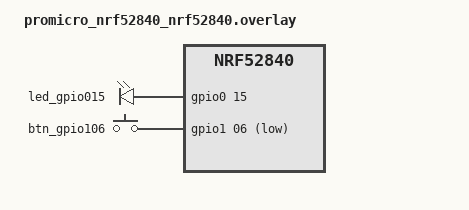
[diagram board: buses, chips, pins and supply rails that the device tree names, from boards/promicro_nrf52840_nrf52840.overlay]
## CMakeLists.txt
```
cmake_minimum_required(VERSION 3.20.0)

find_package(Zephyr)
project(keebz)

target_sources(app PRIVATE src/keebz_usb_hid.c src/keebz_usb_dev.c)
```

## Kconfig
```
# SPDX-License-Identifier: Apache-2.0

mainmenu "Keebz"

menu "Application"

config KEEBZ_USB_HID_LOG_LEVEL
	int "Keebz USB HID thread log level"
	depends on LOG
	default 0

config KEEBZ_USB_DEV_LOG_LEVEL
	int "Keebz USB device thread log level"
	depends on LOG
	default 0

config KEEBZ_USB_DEV_VENDOR_ID
	hex "Keebz USB device vendor id"
	default 0x0000

config KEEBZ_USB_DEV_PRODUCT_ID
	hex "Keebz USB device product id"
	default 0x0000

config KEEBZ_USB_DEV_MANUFACTURER
	string "Keebz USB device manufacturer string"
	default "Unknown"

config KEEBZ_USB_DEV_PRODUCT
	string "Keebz USB device product string"
	default "Unknown"

config KEEBZ_USB_DEV_SELF_POWERED
	bool "Keebz USB device self-powered attribute"
	default n

config KEEBZ_USB_DEV_REMOTE_WAKEUP
	bool "Keebz USB device remote wakeup attribute"
	default n

config KEEBZ_USB_DEV_MAX_POWER
	int "Keebz USB device max power value (in 2mA units)"
	default 125
	range 0 250

config KEEBZ_USB_DEV_20_EXT_DESC
	bool "Keebz USB device to use USB 2.0 extension descriptor"
	default true

endmenu

source "Kconfig.zephyr"
```

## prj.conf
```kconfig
CONFIG_ASSERT=y
CONFIG_GPIO=y
CONFIG_POLL=y
CONFIG_SCHED_DUMB=y

CONFIG_SERIAL=y
CONFIG_CONSOLE=y
CONFIG_UART_CONSOLE=y
CONFIG_INPUT=y
CONFIG_INPUT_GPIO_KEYS=y

CONFIG_LOG=y
CONFIG_LOG_MODE_DEFERRED=y
CONFIG_LOG_DEFAULT_LEVEL=0
CONFIG_LOG_BACKEND_UART=y

CONFIG_USB_DEVICE_STACK=n
CONFIG_USB_CDC_ACM=n
CONFIG_USB_DEVICE_STACK_NEXT=y
CONFIG_USBD_HID_SUPPORT=y

# CONFIG_USBD_LOG_LEVEL_DBG=y
# CONFIG_UDC_DRIVER_LOG_LEVEL_DBG=y
# CONFIG_NRF_USBD_COMMON_LOG_LEVEL_DBG=y
CONFIG_KEEBZ_USB_HID_LOG_LEVEL=4
CONFIG_KEEBZ_USB_DEV_LOG_LEVEL=4
CONFIG_KEEBZ_USB_DEV_VENDOR_ID=0x2fe3
CONFIG_KEEBZ_USB_DEV_PRODUCT_ID=0x0007
CONFIG_KEEBZ_USB_DEV_MANUFACTURER="Boardsource"
CONFIG_KEEBZ_USB_DEV_PRODUCT="Microdox Bud v2"
```

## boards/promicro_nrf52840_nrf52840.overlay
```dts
/ {
	chosen {
		zephyr,console = &uart0;
	};
	aliases {
		led-alive = &led_gpio015;
		btn-key = &btn_gpio106;
 		hid-kbd = &hid_kbd0;
	};
	leds {
		compatible = "gpio-leds";
		led_gpio015: led_gpio015 {
			gpios = <&gpio0 15 GPIO_ACTIVE_HIGH>;
			status = "okay";
		};
	};
	buttons {
		compatible = "gpio-keys";
		btn_gpio106: btn_gpio106 {
			zephyr,code = <INPUT_KEY_0>;
			gpios = <&gpio1 06 (GPIO_PULL_UP | GPIO_ACTIVE_LOW)>;
			status = "okay";
		};
	};
	hid_kbd0: hid_kbd0 {
		compatible = "zephyr,hid-device";
		interface-name = "HID0";
		protocol-code = "keyboard";
		in-report-size = <64>;
		in-polling-period-us = <125>;
		out-report-size = <64>;
		out-polling-period-us = <125>;
		status = "okay";
	};
};
```

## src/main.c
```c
#include <stdio.h>
#include <zephyr/kernel.h>
#include <zephyr/drivers/gpio.h>

#define SLEEP_TIME_MS 200

#define LED0_NODE DT_ALIAS(led_alive)

static const struct gpio_dt_spec led = GPIO_DT_SPEC_GET(LED0_NODE, gpios);

int main(void)
{
	int ret;
	bool led_state = true;

	if (!gpio_is_ready_dt(&led)) {
		return 0;
	}

	ret = gpio_pin_configure_dt(&led, GPIO_OUTPUT_ACTIVE);
	if (ret < 0) {
		return 0;
	}

	while (1) {
		ret = gpio_pin_toggle_dt(&led);
		if (ret < 0) {
			return 0;
		}

		led_state = !led_state;
		printf("LED state: %s\n", led_state ? "ON" : "OFF");
		k_msleep(SLEEP_TIME_MS);
	}
	return 0;
}
```

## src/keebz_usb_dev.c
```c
#include <stdint.h>

#include <zephyr/device.h>
#include <zephyr/usb/usbd.h>
#include <zephyr/usb/bos.h>
#include <zephyr/logging/log.h>

#include "keebz_usb_dev.h"

LOG_MODULE_REGISTER(keebz_usb_dev, CONFIG_KEEBZ_USB_DEV_LOG_LEVEL);

USBD_DEVICE_DEFINE(keebz_usb_dev, DEVICE_DT_GET(DT_NODELABEL(zephyr_udc0)), CONFIG_KEEBZ_USB_DEV_VENDOR_ID,
		   CONFIG_KEEBZ_USB_DEV_PRODUCT_ID);

static const char *const keebz_usb_dev_blocklist[] = { "dfu_dfu", NULL };

USBD_DESC_LANG_DEFINE(keebz_usb_dev_lang);
USBD_DESC_MANUFACTURER_DEFINE(keebz_usb_dev_mfr, CONFIG_KEEBZ_USB_DEV_MANUFACTURER);
USBD_DESC_PRODUCT_DEFINE(keebz_usb_dev_product, CONFIG_KEEBZ_USB_DEV_PRODUCT);
USBD_DESC_SERIAL_NUMBER_DEFINE(keebz_usb_dev_serial);

USBD_DESC_CONFIG_DEFINE(keebz_usb_dev_fs_desc, "Full-speed configuration");
USBD_DESC_CONFIG_DEFINE(keebz_usb_dev_hs_desc, "High-speed configuration");

static const uint8_t attributes = (IS_ENABLED(CONFIG_KEEBZ_USB_DEV_SELF_POWERED) ? USB_SCD_SELF_POWERED : 0) |
				  (IS_ENABLED(CONFIG_KEEBZ_USB_DEV_REMOTE_WAKEUP) ? USB_SCD_REMOTE_WAKEUP : 0);

USBD_CONFIGURATION_DEFINE(keebz_usb_dev_fs_cfg, attributes, CONFIG_KEEBZ_USB_DEV_MAX_POWER, &keebz_usb_dev_fs_desc);
USBD_CONFIGURATION_DEFINE(keebz_usb_dev_hs_cfg, attributes, CONFIG_KEEBZ_USB_DEV_MAX_POWER, &keebz_usb_dev_hs_desc);

static const struct usb_bos_capability_lpm keebz_usb_dev_bos_cap_lpm = {
	.bLength = sizeof(struct usb_bos_capability_lpm),
	.bDescriptorType = USB_DESC_DEVICE_CAPABILITY,
	.bDevCapabilityType = USB_BOS_CAPABILITY_EXTENSION,
	.bmAttributes = 0UL,
};

USBD_DESC_BOS_DEFINE(keebz_usb_dev_ext_desc, sizeof(keebz_usb_dev_bos_cap_lpm), &keebz_usb_dev_bos_cap_lpm);

static void keebz_usb_dev_fix_code_triple(struct usbd_context *ctx, const enum usbd_speed speed)
{
	if (IS_ENABLED(CONFIG_USBD_CDC_ACM_CLASS) || IS_ENABLED(CONFIG_USBD_CDC_ECM_CLASS) ||
	    IS_ENABLED(CONFIG_USBD_CDC_NCM_CLASS) || IS_ENABLED(CONFIG_USBD_MIDI2_CLASS) ||
	    IS_ENABLED(CONFIG_USBD_AUDIO2_CLASS)) {
		usbd_device_set_code_triple(ctx, speed, USB_BCC_MISCELLANEOUS, 0x02, 0x01);
	} else {
		usbd_device_set_code_triple(ctx, speed, 0, 0, 0);
	}
}

struct usbd_context *keebz_usb_dev_init(usbd_msg_cb_t cb)
{
	int err;

	if (!keebz_usb_dev_setup(cb)) {
		LOG_ERR("Failed to setup device");
		return NULL;
	}

	err = usbd_init(&keebz_usb_dev);
	if (err) {
		LOG_ERR("Failed to initialize device support, err=%d", err);
		return NULL;
	}

	return &keebz_usb_dev;
}

struct usbd_context *keebz_usb_dev_setup(usbd_msg_cb_t cb)
{
	int err;

	err = usbd_add_descriptor(&keebz_usb_dev, &keebz_usb_dev_lang);
	if (err) {
		LOG_ERR("Failed to initialize language descriptor, err=%d", err);
		return NULL;
	}

	err = usbd_add_descriptor(&keebz_usb_dev, &keebz_usb_dev_mfr);
	if (err) {
		LOG_ERR("Failed to initialize manufacturer descriptor, err=%d", err);
		return NULL;
	}

	err = usbd_add_descriptor(&keebz_usb_dev, &keebz_usb_dev_product);
	if (err) {
		LOG_ERR("Failed to initialize product descriptor, err=%d", err);
		return NULL;
	}

	err = usbd_add_descriptor(&keebz_usb_dev, &keebz_usb_dev_serial);
	if (err) {
		LOG_ERR("Failed to initialize serial number descriptor, err=%d", err);
		return NULL;
	}

	if (usbd_caps_speed(&keebz_usb_dev) == USBD_SPEED_HS) {
		err = usbd_add_configuration(&keebz_usb_dev, USBD_SPEED_HS, &keebz_usb_dev_hs_cfg);
		if (err) {
			LOG_ERR("Failed to add high-speed configuration, err=%d", err);
			return NULL;
		}

		err = usbd_register_all_classes(&keebz_usb_dev, USBD_SPEED_HS, 1, keebz_usb_dev_blocklist);
		if (err) {
			LOG_ERR("Failed to add register classes for high-speed configuration, err=%d", err);
			return NULL;
		}

		keebz_usb_dev_fix_code_triple(&keebz_usb_dev, USBD_SPEED_HS);
	}

	err = usbd_add_configuration(&keebz_usb_dev, USBD_SPEED_FS, &keebz_usb_dev_fs_cfg);
	if (err) {
		LOG_ERR("Failed to add full-speed configuration, err=%d", err);
		return NULL;
	}

	err = usbd_register_all_classes(&keebz_usb_dev, USBD_SPEED_FS, 1, keebz_usb_dev_blocklist);
	if (err) {
		LOG_ERR("Failed to add register classes for full-speed configuration, err=%d", err);
		return NULL;
	}

	keebz_usb_dev_fix_code_triple(&keebz_usb_dev, USBD_SPEED_FS);
	usbd_self_powered(&keebz_usb_dev, attributes & USB_SCD_SELF_POWERED);

	if (cb) {
		err = usbd_msg_register_cb(&keebz_usb_dev, cb);
		if (err) {
			LOG_ERR("Failed to register message callback, err=%d", err);
			return NULL;
		}
	}

	if (IS_ENABLED(CONFIG_KEEBZ_USB_DEV_20_EXT_DESC)) {
		(void)usbd_device_set_bcd_usb(&keebz_usb_dev, USBD_SPEED_FS, 0x0201);
		(void)usbd_device_set_bcd_usb(&keebz_usb_dev, USBD_SPEED_HS, 0x0201);

		err = usbd_add_descriptor(&keebz_usb_dev, &keebz_usb_dev_ext_desc);
		if (err) {
			LOG_ERR("Failed to add USB 2.0 extension descriptor, err=%d", err);
			return NULL;
		}
	}

	return &keebz_usb_dev;
}
```

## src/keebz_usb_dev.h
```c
#ifndef KEEBZ_USB_DEV_H
#define KEEBZ_USB_DEV_H

#include <stdint.h>

#include <zephyr/usb/usbd.h>

struct usbd_context *keebz_usb_dev_init(usbd_msg_cb_t cb);
struct usbd_context *keebz_usb_dev_setup(usbd_msg_cb_t cb);

#endif /* KEEBZ_USB_DEV_H */
```

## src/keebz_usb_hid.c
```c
#include <stdint.h>

#include <zephyr/kernel.h>
#include <zephyr/drivers/gpio.h>
#include <zephyr/drivers/usb/usb_dc.h>
#include <zephyr/usb/usbd.h>
#include <zephyr/usb/usb_device.h>
#include <zephyr/usb/class/hid.h>
#include <zephyr/usb/class/usb_hid.h>
#include <zephyr/usb/class/usbd_hid.h>
#include <zephyr/input/input.h>
#include <zephyr/logging/log.h>

#include "keebz_usb_dev.h"

LOG_MODULE_REGISTER(keebz_usb_hid, CONFIG_KEEBZ_USB_HID_LOG_LEVEL);

#define SLEEP_TIME_MS 3000
static const struct gpio_dt_spec led = GPIO_DT_SPEC_GET(DT_ALIAS(led_alive), gpios);
static const uint8_t hid_report_desc[] = HID_KEYBOARD_REPORT_DESC();

static bool kb_ready;
static uint32_t kb_duration;

struct kb_event {
	uint16_t code;
	int32_t value;
};

enum kb_report_idx {
	KB_MOD_KEY = 0,
	KB_RESERVED,
	KB_KEY_CODE1,
	KB_KEY_CODE2,
	KB_KEY_CODE3,
	KB_KEY_CODE4,
	KB_KEY_CODE5,
	KB_KEY_CODE6,
	KB_REPORT_COUNT,
};

K_MSGQ_DEFINE(kb_msgq, sizeof(struct kb_event), 2, 1);
UDC_STATIC_BUF_DEFINE(report, KB_REPORT_COUNT);
struct kb_event kb_evt;

static void input_cb(struct input_event *evt, void *user_data)
{
	ARG_UNUSED(user_data);

	kb_evt.code = evt->code;
	kb_evt.value = evt->value;
	LOG_INF("Got new event code=%d, value=%d", kb_evt.code, kb_evt.value);

	if (k_msgq_put(&kb_msgq, &kb_evt, K_NO_WAIT) != 0) {
		LOG_ERR("Failed to put new input event");
	}
}

INPUT_CALLBACK_DEFINE(NULL, input_cb, NULL);

static void msg_cb(struct usbd_context *const usbd_ctx, const struct usbd_msg *const msg)
{
	LOG_INF("USBD message: %s", usbd_msg_type_string(msg->type));

	if (msg->type == USBD_MSG_CONFIGURATION) {
		LOG_INF("\tConfiguration value %d", msg->status);
	}

	if (usbd_can_detect_vbus(usbd_ctx)) {
		if (msg->type == USBD_MSG_VBUS_READY) {
			if (usbd_enable(usbd_ctx)) {
				LOG_ERR("Failed to enable device support");
			}
		}

		if (msg->type == USBD_MSG_VBUS_REMOVED) {
			if (usbd_disable(usbd_ctx)) {
				LOG_ERR("Failed to disable device support");
			}
		}
	}
}
static void kb_iface_ready(const struct device *dev, const bool ready)
{
	LOG_INF("HID device %s interface is %s", dev->name, ready ? "ready" : "not ready");
	kb_ready = ready;
}

static int kb_get_report(const struct device *dev, const uint8_t type, const uint8_t id, const uint16_t len,
			 uint8_t *const buf)
{
	LOG_WRN("Get Report not implemented, Type %u ID %u", type, id);

	return 0;
}

static int kb_set_report(const struct device *dev, const uint8_t type, const uint8_t id, const uint16_t len,
			 const uint8_t *const buf)
{
	if (type != HID_REPORT_TYPE_OUTPUT) {
		LOG_WRN("Unsupported report type");
		return -ENOTSUP;
	}

	LOG_HEXDUMP_INF(buf, len, "set report");

	return 0;
}

static void kb_set_idle(const struct device *dev, const uint8_t id, const uint32_t duration)
{
	LOG_INF("Set Idle %u to %u", id, duration);
	kb_duration = duration;
}

static uint32_t kb_get_idle(const struct device *dev, const uint8_t id)
{
	LOG_INF("Get Idle %u to %u", id, kb_duration);
	return kb_duration;
}

static void kb_set_protocol(const struct device *dev, const uint8_t proto)
{
	LOG_INF("Protocol changed to %s", proto == 0U ? "Boot Protocol" : "Report Protocol");
}

static void kb_output_report(const struct device *dev, const uint16_t len, const uint8_t *const buf)
{
	LOG_HEXDUMP_INF(buf, len, "output report");
	kb_set_report(dev, HID_REPORT_TYPE_OUTPUT, 0U, len, buf);
}

struct hid_device_ops kb_ops = {
	.iface_ready = kb_iface_ready,
	.get_report = kb_get_report,
	.set_report = kb_set_report,
	.set_idle = kb_set_idle,
	.get_idle = kb_get_idle,
	.set_protocol = kb_set_protocol,
	.output_report = kb_output_report,
};

int main(void)
{
	int err;
	bool led_state = true;
	const struct device *hid_dev;
	struct usbd_context *sample_usbd;

	LOG_INF("Main started...");

	hid_dev = DEVICE_DT_GET(DT_ALIAS(hid_kbd));
	if (!device_is_ready(hid_dev)) {
		LOG_ERR("HID Device is not ready");
		return -EIO;
	}

	err = hid_device_register(hid_dev, hid_report_desc, sizeof(hid_report_desc), &kb_ops);
	if (err != 0) {
		LOG_ERR("Failed to register HID Device, %d", err);
		return err;
	}

	sample_usbd = keebz_usb_dev_init(msg_cb);
	if (sample_usbd == NULL) {
		LOG_ERR("Failed to initialize USB device");
		return -ENODEV;
	}

	if (!usbd_can_detect_vbus(sample_usbd)) {
		err = usbd_enable(sample_usbd);
		if (err) {
			LOG_ERR("Failed to enable device support");
			return err;
		}
	}

	LOG_INF("HID keyboard sample is initialized");

	if (!gpio_is_ready_dt(&led)) {
		LOG_ERR("LED GPIO not ready");
		return -EIO;
	}

	err = gpio_pin_configure_dt(&led, GPIO_OUTPUT_ACTIVE);
	if (err < 0) {
		LOG_ERR("Failed to configure LED GPIO");
		return -EIO;
	}

	while (true) {
		struct kb_event kb_evt;

		k_msgq_get(&kb_msgq, &kb_evt, K_FOREVER);

		switch (kb_evt.code) {
		case INPUT_KEY_0:
			if (kb_evt.value) {
				report[KB_KEY_CODE1] = HID_KEY_1;
			} else {
				report[KB_KEY_CODE1] = 0;
			}
			break;
		default:
			LOG_ERR("Unrecognized input code %u value %d", kb_evt.code, kb_evt.value);
			continue;
		}

		if (!kb_ready) {
			LOG_WRN("USB HID device is not ready");
			continue;
		}

		err = hid_device_submit_report(hid_dev, KB_REPORT_COUNT, report);
		if (err) {
			LOG_ERR("HID submit report error, %d", err);
		} else {
			LOG_INF("HID submit report");
		}
	}

	while (true) {
		err = gpio_pin_toggle_dt(&led);
		if (err < 0) {
			LOG_ERR("Failed to toggle LED GPIO");
			return -EIO;
		}

		led_state = !led_state;
		k_msleep(SLEEP_TIME_MS);
	}

	return 0;
}
```
